# ESP32C5_RADIO register map
Vendor: Espressif; Series: ESP32-C5; File version: 0.1
Registers are 32-bit, read-write, no defined reset value unless marked. A register's access mark holds for its fields unless they carry their own. Offsets are from the block's base; [hi:lo] are bit positions; {n}, {i} and the like mark numbered series.

## WIFI_MAC_STA_BEACON_FILTER — Station beacon-filter control word recovered from the complete enable and disable leaves. The three low bits are toggled together; individual hardware meanings remain unknown.
Base 0x600A42B4
0x00 CONTROL — Project-assigned name. hal_enable_sta_beacon_filter sets bits 2:0 after enabling the matching interrupt; hal_disable_sta_beacon_filter clears them before disabling that interrupt.
  [2:0] BITS_0_2_OPAQUE — Opaque: meaning not established.

## WIFI_MAC_STA_TSF_LOAD — Shared station TSF load and coherent snapshot transaction.
Base 0x600AD814
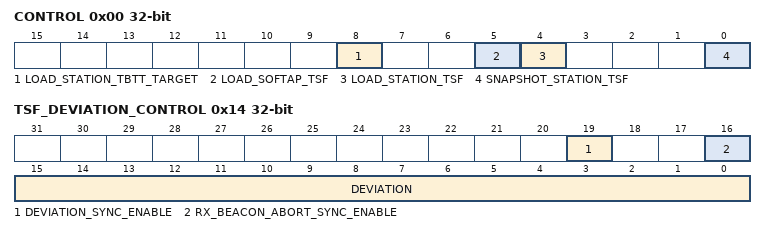
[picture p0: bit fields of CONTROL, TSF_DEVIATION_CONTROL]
0x00 CONTROL — Project-assigned name. Complete hal_set_sta_tsf asserts bit four after writing both station TSF value words; the SoftAP path of complete hal_mac_tsf_reset asserts bit five after clearing both shared TSF value words; complete libpp[hal_tsf.o]::hal_get_sta_tsf sets then clears bit zero around its snapshot reads.
  [8] LOAD_STATION_TBTT_TARGET — Project-assigned name. Complete hal_set_sta_tbtt and the index-0 TBTT start-time leaf set this bit after writing the station TBTT target.
  [5] LOAD_SOFTAP_TSF — Project-assigned name. SoftAP TSF load request asserted after the two zero-value writes by the arg0=0 path of complete hal_mac_tsf_reset.
  [4] LOAD_STATION_TSF — Project-assigned name. Station TSF load request asserted by the final fresh-read RMW in hal_set_sta_tsf.
  [0] SNAPSHOT_STATION_TSF — Project-assigned name. Complete libpp[hal_tsf.o]::hal_get_sta_tsf sets this bit before either station TSF word is sampled and clears it after the optional reads.
0x04 VALUE_LOW wo — Project-assigned name. Low 32 bits written first by complete hal_set_sta_tsf.
  [31:0] VALUE — Project-assigned name.
0x08 VALUE_HIGH wo — Project-assigned name. High 32 bits written second by complete hal_set_sta_tsf.
  [31:0] VALUE — Project-assigned name.
0x0C SNAPSHOT_LOW ro — Project-assigned name. Coherently latched low 32 bits conditionally read by complete libpp[hal_tsf.o]::hal_get_sta_tsf.
  [31:0] VALUE — Project-assigned name.
0x10 SNAPSHOT_HIGH ro — Project-assigned name. Coherently latched high 32 bits conditionally read by complete libpp[hal_tsf.o]::hal_get_sta_tsf.
  [31:0] VALUE — Project-assigned name.
0x14 TSF_DEVIATION_CONTROL — Project-assigned name. Complete ROM leaves independently replace the TSF deviation value and set two synchronization controls; omitted bits remain semantically unknown.
  [19] DEVIATION_SYNC_ENABLE — Project-assigned name.
  [16] RX_BEACON_ABORT_SYNC_ENABLE — Project-assigned name.
  [15:0] DEVIATION — Project-assigned name.

## WIFI_MAC_TX_COMMON — Shared Wi-Fi CCA, timeout and completion state used by MAC transmit queues and the PHY-owned Wi-Fi CCA gate.
Base 0x600A4C5C
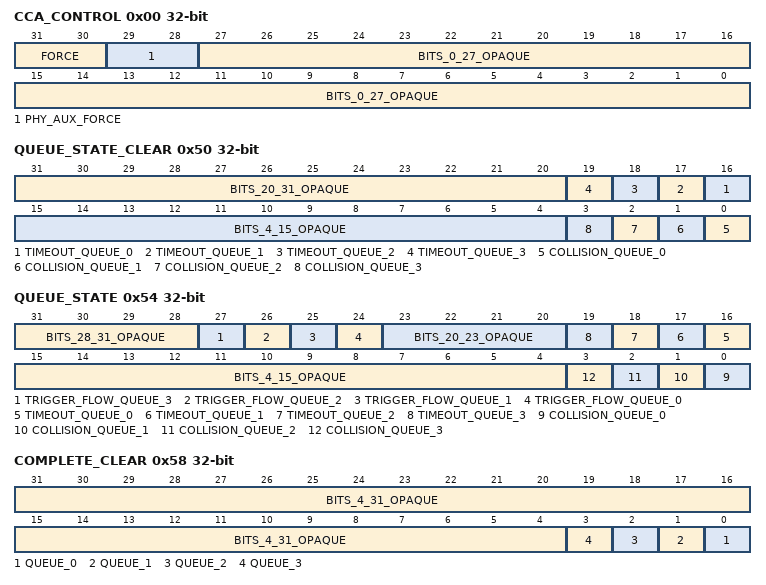
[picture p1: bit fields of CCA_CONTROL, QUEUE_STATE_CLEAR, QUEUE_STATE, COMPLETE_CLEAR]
0x00 CCA_CONTROL — Project-assigned name. Global Wi-Fi TX CCA control; complete PHY enable/disable leaves update the high two fields through separate fresh reads.
  [31:30] FORCE — Project-assigned name. Value three suppresses CCA while invalidating a timed-out queue. Complete libphy[phy_reg.o]::phy_disable_cca writes encoding two and complete libphy[phy_reg.o]::phy_enable_cca writes zero.
  [29:28] PHY_AUX_FORCE — Project-assigned name. Complete libphy[phy_reg.o]::phy_disable_cca writes encoding two and complete libphy[phy_reg.o]::phy_enable_cca writes zero in their second fresh-read edge.
  [27:0] BITS_0_27_OPAQUE — Opaque: meaning not established.
0x50 QUEUE_STATE_CLEAR wo write-1-clears — Project-assigned name. Queue collision/timeout state acknowledgement.
  [31:20] BITS_20_31_OPAQUE — Opaque: meaning not established.
  [n+16] TIMEOUT_QUEUE_{n} (n=0..3) — Project-assigned name.
  [15:4] BITS_4_15_OPAQUE — Opaque: meaning not established.
  [n] COLLISION_QUEUE_{n} (n=0..3) — Project-assigned name.
0x54 QUEUE_STATE ro — Project-assigned name. Per-queue timeout and trigger-flow state. The complete trigger-flow HAL getter returns the entire high byte; the complete completion dispatcher then right-shifts it by the completed queue number and tests bit zero.
  [31:28] BITS_28_31_OPAQUE — Opaque: meaning not established. The complete HAL returns four additional high bitmap bits whose bounded ordinary-queue meaning remains unresolved.
  [27] TRIGGER_FLOW_QUEUE_3 — Project-assigned name.
  [26] TRIGGER_FLOW_QUEUE_2 — Project-assigned name.
  [25] TRIGGER_FLOW_QUEUE_1 — Project-assigned name.
  [24] TRIGGER_FLOW_QUEUE_0 — Project-assigned name. Queue zero is participating in the hardware Trigger-based transmit flow.
  [23:20] BITS_20_23_OPAQUE — Opaque: meaning not established.
  [n+16] TIMEOUT_QUEUE_{n} (n=0..3) — Project-assigned name.
  [15:4] BITS_4_15_OPAQUE — Opaque: meaning not established.
  [n] COLLISION_QUEUE_{n} (n=0..3) — Project-assigned name.
0x58 COMPLETE_CLEAR write-1-clears — Project-assigned name. Preserved-image acknowledgement for ordinary queue completion bits.
  [31:4] BITS_4_31_OPAQUE — Opaque: meaning not established.
  [n] QUEUE_{n} (n=0..3) — Project-assigned name.
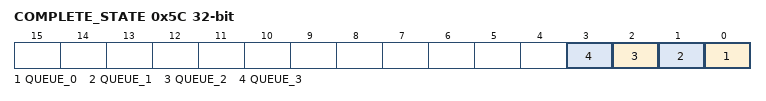
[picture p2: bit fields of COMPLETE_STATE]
0x5C COMPLETE_STATE ro — Project-assigned name. Low four bits report completed ordinary queues 0..3.
  [n] QUEUE_{n} (n=0..3) — Project-assigned name.

## WIFI_MAC_INTERFACE_ADDRESS — Four interface-address pairs consumed by MAC receive filtering.
Base 0x600A405C
{0x0+8i} ADDRESS_LOW{i} (i=0..3) — Project-assigned name. Interface MAC bytes 0..3 in little-endian order, published by the first full-word store.
  [31:0] BYTES_0_3 — Project-assigned name.
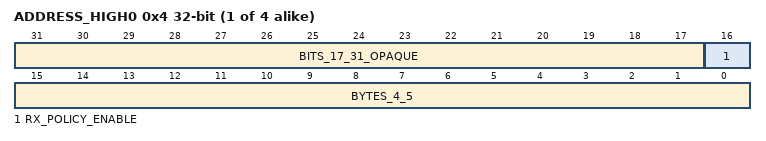
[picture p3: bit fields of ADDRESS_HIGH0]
{0x4+8i} ADDRESS_HIGH{i} (i=0..3) — Project-assigned name. Interface MAC bytes 4..5 are published as a full-word store before a separate fresh-read RMW sets receive-policy enable bit 16.
  [31:17] BITS_17_31_OPAQUE — Opaque: meaning not established.
  [16] RX_POLICY_ENABLE — Project-assigned name. Set by a separate fresh-read RMW in hal_mac_set_addr and by the reachable associated-STA policy branch.
  [15:0] BYTES_4_5 — Project-assigned name.
